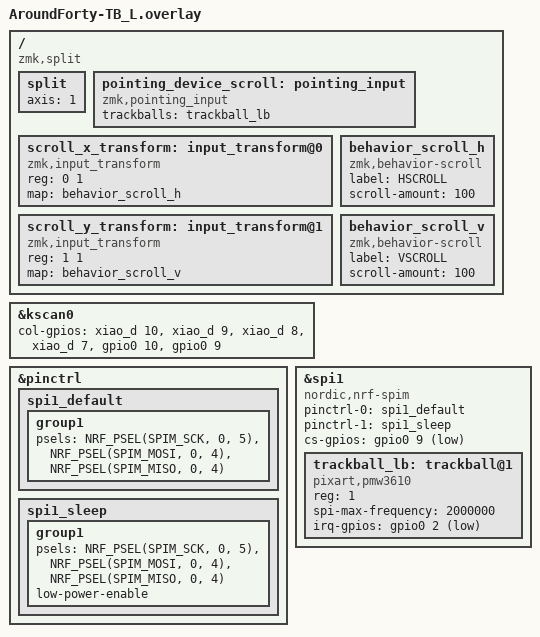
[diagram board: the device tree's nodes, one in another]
#include "AroundForty-TB.dtsi"

/* --- キー行列定義（既存のまま） */
&kscan0 {
    col-gpios = 
        <&xiao_d 10 GPIO_ACTIVE_HIGH>,
        <&xiao_d 9  GPIO_ACTIVE_HIGH>,
        <&xiao_d 8  GPIO_ACTIVE_HIGH>,
        <&xiao_d 7  GPIO_ACTIVE_HIGH>,
        <&gpio0 10 GPIO_ACTIVE_HIGH>,
        <&gpio0  9 GPIO_ACTIVE_HIGH>;
};

/* --- 1) SPI1 pinctrl 定義 --- */
&pinctrl {
    spi1_default: spi1_default {
        group1 {
            psels = 
                <NRF_PSEL(SPIM_SCK,  0, 5)>,
                <NRF_PSEL(SPIM_MOSI, 0, 4)>,
                <NRF_PSEL(SPIM_MISO, 0, 4)>;
        };
    };
    spi1_sleep: spi1_sleep {
        group1 {
            psels = 
                <NRF_PSEL(SPIM_SCK,  0, 5)>,
                <NRF_PSEL(SPIM_MOSI, 0, 4)>,
                <NRF_PSEL(SPIM_MISO, 0, 4)>;
            low-power-enable;
        };
    };
};

/* --- 2) SPI1 本体設定 --- */
&spi1 {
    status        = "okay";
    compatible    = "nordic,nrf-spim";
    pinctrl-0     = <&spi1_default>;
    pinctrl-1     = <&spi1_sleep>;
    pinctrl-names = "default", "sleep";

    cs-gpios      = <&gpio0 9 GPIO_ACTIVE_LOW>;

    trackball_lb: trackball@1 {
        compatible        = "pixart,pmw3610";
        reg               = <1>;
        spi-max-frequency = <2000000>;
        irq-gpios         = <&gpio0 2 (GPIO_ACTIVE_LOW | GPIO_PULL_UP)>;
        status            = "okay";
    };
};

/* --- 3) Split クライアント化 & スクロール定義 --- */
 / {
    compatible = "zmk,split";
    split {
        status = "okay";
        axis   = <1>;
    };

    /* スクロール入力デバイス */
    pointing_device_scroll: pointing_input {
        compatible = "zmk,pointing_input";
        trackballs = <&trackball_lb>;
        status     = "okay";
    };

    /* 水平スクロール変換 */
    scroll_x_transform: input_transform@0 {
        compatible = "zmk,input_transform";
        reg        = <0 1>;
        map        = <&behavior_scroll_h>;
    };

    /* 垂直スクロール変換 */
    scroll_y_transform: input_transform@1 {
        compatible = "zmk,input_transform";
        reg        = <1 1>;
        map        = <&behavior_scroll_v>;
    };

    /* スクロールビヘイビア */
    behavior_scroll_h: behavior_scroll_h {
        compatible    = "zmk,behavior-scroll";
        label         = "HSCROLL";
        scroll-amount = <100>;
    };

    behavior_scroll_v: behavior_scroll_v {
        compatible    = "zmk,behavior-scroll";
        label         = "VSCROLL";
        scroll-amount = <100>;
    };
};
